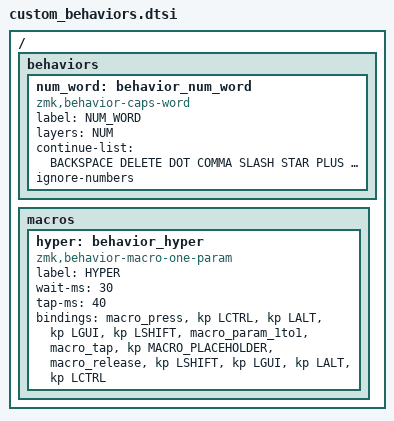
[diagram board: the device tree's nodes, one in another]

/ {
    behaviors {
        num_word: behavior_num_word {
            compatible = "zmk,behavior-caps-word";
            label = "NUM_WORD";
            #binding-cells = <0>;
            layers = <NUM>;         // insert location of numbers layer here
            continue-list = <BACKSPACE DELETE DOT COMMA SLASH STAR PLUS EQUAL MINUS COLON ENTER>; 
            ignore-numbers;         // numbers don't deactivate the layer
        };
    };
    macros { 
        hyper: behavior_hyper {
            compatible = "zmk,behavior-macro-one-param";
            label = "HYPER";
            wait-ms = <30>;
            tap-ms = <40>;
            #binding-cells = <1>;
            bindings = 
                <&macro_press &kp LCTRL &kp LALT &kp LGUI &kp LSHIFT>,
                <&macro_param_1to1>, <&macro_tap &kp MACRO_PLACEHOLDER>,
                <&macro_release &kp LSHIFT &kp LGUI &kp LALT &kp LCTRL>;
        };
    };
};

// home row mods

ZMK_BEHAVIOR(hml, hold_tap,
    flavor = "balanced";
    tapping-term-ms = <TAPPING_TERM_MS>;
    quick-tap-ms = <QUICK_TAP_MS>;
    require-prior-idle-ms = <PRIOR_IDLE_MS>;
    bindings = <&kp>, <&kp>;
    hold-trigger-key-positions = <KEYS_R THUMBS>;
    hold-trigger-on-release;
)

ZMK_BEHAVIOR(hmr, hold_tap,
    flavor = "balanced";
    tapping-term-ms = <TAPPING_TERM_MS>;
    quick-tap-ms = <QUICK_TAP_MS>;
    require-prior-idle-ms = <PRIOR_IDLE_MS>;
    bindings = <&kp>, <&kp>;
    hold-trigger-key-positions = <KEYS_L THUMBS>;
    hold-trigger-on-release;
)

// thumbs 

ZMK_BEHAVIOR(th_ht, hold_tap, 
    flavor = "balanced";
    tapping-term-ms = <160>;
    bindings = <&kp>, <&kp>;
)

